AUTOSAR XML (schema 4.0)
package /ADAS_Components
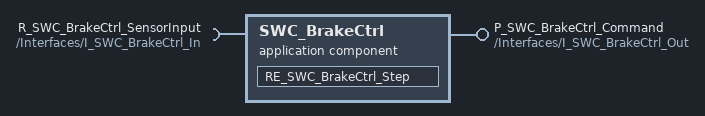
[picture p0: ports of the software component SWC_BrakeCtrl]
  application sw component type SWC_BrakeCtrl  # AUTOSAR Application SWC SWC_BrakeCtrl for ADAS control
    provide port P_SWC_BrakeCtrl_Command: provided-interface=/Interfaces/I_SWC_BrakeCtrl_Out
    require port R_SWC_BrakeCtrl_SensorInput: required-interface=/Interfaces/I_SWC_BrakeCtrl_In
    behavior SWC_BrakeCtrl_Behavior
      runnable RE_SWC_BrakeCtrl_Step: symbol=SWC_BrakeCtrl_Step
